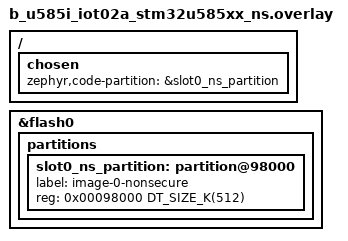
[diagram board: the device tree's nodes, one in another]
/*
 * Copyright (c) 2022, STMicroelectronics
 *
 * SPDX-License-Identifier: Apache-2.0
 */
/ {
	chosen {
		zephyr,code-partition = &slot0_ns_partition;
	};
};

&flash0 {
	partitions {
		/delete-node/ slot0_partition;
		/* Non-secure image primary slot */
		slot0_ns_partition: partition@98000 {
			label = "image-0-nonsecure";
			reg = <0x00098000 DT_SIZE_K(512)>;
		};
	};
};
